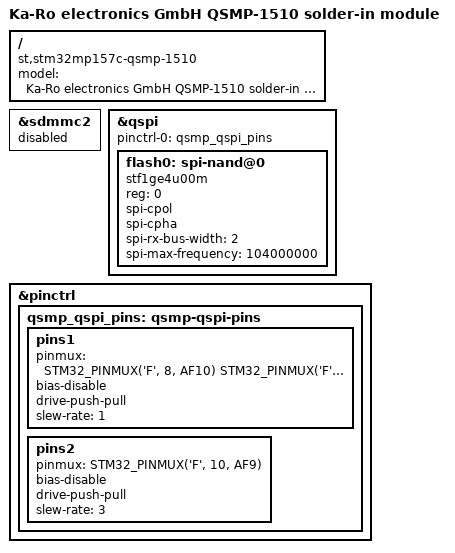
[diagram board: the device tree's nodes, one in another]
// SPDX-License-Identifier: (GPL-2.0+ OR BSD-3-Clause)
/*
 * Copyright (C) STMicroelectronics 2019 - All Rights Reserved
 * Author: STM32CubeMX code generation for STMicroelectronics.
 */

/dts-v1/;

#include "stm32mp151a-qsmp.h"
#include "stm32mp15-qsmp.dtsi"

/ {
	model = "Ka-Ro electronics GmbH QSMP-1510 solder-in module";
	compatible = "st,stm32mp157c-qsmp-1510", "st,stm32mp151";
};

&sdmmc2 {
	status = "disabled";
};

&qspi {
	pinctrl-names = "default";
	pinctrl-0 = <&qsmp_qspi_pins>;
	status = "okay";

	flash0: spi-nand@0 {
		compatible = "stf1ge4u00m", "spi-nand";
		reg = <0>;
		spi-cpol;
		spi-cpha;
		spi-rx-bus-width = <2>;
		spi-max-frequency = <104000000>;
		status = "okay";
	};
};

&pinctrl {
	 qsmp_qspi_pins: qsmp-qspi-pins {
	 	pins1 {
			pinmux = <
				  STM32_PINMUX('F', 8, AF10) /* QSPI_BK1_IO0 */
				  STM32_PINMUX('F', 9, AF10) /* QSPI_BK1_IO1 */
			>;
			bias-disable;
			drive-push-pull;
			slew-rate = <1>;
		};

	 	pins2 {
			pinmux = <STM32_PINMUX('F', 10, AF9)>; /* QSPI_CLK */
			bias-disable;
			drive-push-pull;
			slew-rate = <3>;
		};
	};
};
